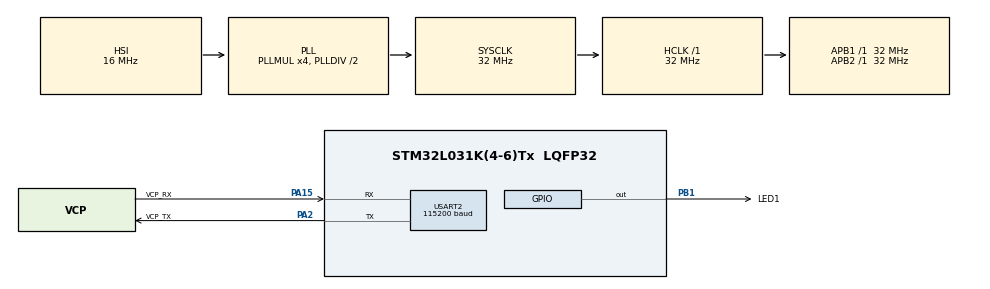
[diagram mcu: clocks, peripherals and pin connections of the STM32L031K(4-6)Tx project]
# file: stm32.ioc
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Mcu.Family=STM32L0
Mcu.Name=STM32L031K(4-6)Tx
Mcu.Package=LQFP32
NVIC.RTC_IRQn=true\:1\:0\:true\:true\:true\:2\:true
NVIC.USART2_IRQn=true\:2\:0\:true\:true\:true\:1\:true
PA13.GPIO_Label=TMS
PA13.Mode=Serial_Wire
PA13.Signal=SYS_SWDIO
PA14.GPIO_Label=TCK
PA14.Mode=Serial_Wire
PA14.Signal=SYS_SWCLK
PA15.GPIO_Label=VCP_RX
PA15.Mode=Asynchronous
PA15.Signal=USART2_RX
PA2.GPIO_Label=VCP_TX
PA2.Mode=Asynchronous
PA2.Signal=USART2_TX
PB1.GPIO_Label=LED1
PB1.GPIO_Speed=GPIO_SPEED_FREQ_HIGH
PB1.Signal=GPIO_Output
PC14-OSC32_IN.Signal=RCC_OSC32_IN
PC15-OSC32_OUT.Signal=RCC_OSC32_OUT
ProjectManager.HeapSize=0x200
ProjectManager.StackSize=0x400
ProjectManager.TargetToolchain=MDK-ARM V5
RCC.ADCFreq_Value=16000000
RCC.AHBFreq_Value=32000000
RCC.APB1Freq_Value=32000000
RCC.APB1TimFreq_Value=32000000
RCC.APB2Freq_Value=32000000
RCC.APB2TimFreq_Value=32000000
RCC.HCLKFreq_Value=32000000
RCC.HSE_VALUE=8000000
RCC.HSI16_VALUE=16000000
RCC.HSI48_VALUE=48000000
RCC.HSI_VALUE=16000000
RCC.LSE_VALUE=32768
RCC.MSI_VALUE=2097000
RCC.PLLMUL=RCC_PLLMUL_4
RCC.SYSCLKFreq_VALUE=32000000
RCC.SYSCLKSource=RCC_SYSCLKSOURCE_PLLCLK
RCC.VCOOutputFreq_Value=64000000
RTC.WakeUpClock-WakeUp=RTC_WAKEUPCLOCK_CK_SPRE_16BITS
RTC.WakeUpCounter-WakeUp=1
USART2.BaudRate=115200
USART2.VirtualMode-Asynchronous=VM_ASYNC
VP_RTC_VS_RTC_Activate.Mode=RTC_Enabled
VP_RTC_VS_RTC_Calendar.Mode=RTC_Calendar
VP_RTC_VS_RTC_WakeUp_intern.Mode=WakeUp
board=NUCLEO-L031K6

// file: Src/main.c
/* USER CODE BEGIN Header */
/**
  ******************************************************************************
  * @file           : main.c
  * @brief          : Main program body
  ******************************************************************************
  ** This notice applies to any and all portions of this file
  * that are not between comment pairs USER CODE BEGIN and
  * USER CODE END. Other portions of this file, whether
  * inserted by the user or by software development tools
  * are owned by their respective copyright owners.
  *
  * COPYRIGHT(c) 2018 STMicroelectronics
  *
  * Redistribution and use in source and binary forms, with or without modification,
  * are permitted provided that the following conditions are met:
  *   1. Redistributions of source code must retain the above copyright notice,
  *      this list of conditions and the following disclaimer.
  *   2. Redistributions in binary form must reproduce the above copyright notice,
  *      this list of conditions and the following disclaimer in the documentation
  *      and/or other materials provided with the distribution.
  *   3. Neither the name of STMicroelectronics nor the names of its contributors
  *      may be used to endorse or promote products derived from this software
  *      without specific prior written permission.
  *
  * THIS SOFTWARE IS PROVIDED BY THE COPYRIGHT HOLDERS AND CONTRIBUTORS "AS IS"
  * AND ANY EXPRESS OR IMPLIED WARRANTIES, INCLUDING, BUT NOT LIMITED TO, THE
  * IMPLIED WARRANTIES OF MERCHANTABILITY AND FITNESS FOR A PARTICULAR PURPOSE ARE
  * DISCLAIMED. IN NO EVENT SHALL THE COPYRIGHT HOLDER OR CONTRIBUTORS BE LIABLE
  * FOR ANY DIRECT, INDIRECT, INCIDENTAL, SPECIAL, EXEMPLARY, OR CONSEQUENTIAL
  * DAMAGES (INCLUDING, BUT NOT LIMITED TO, PROCUREMENT OF SUBSTITUTE GOODS OR
  * SERVICES; LOSS OF USE, DATA, OR PROFITS; OR BUSINESS INTERRUPTION) HOWEVER
  * CAUSED AND ON ANY THEORY OF LIABILITY, WHETHER IN CONTRACT, STRICT LIABILITY,
  * OR TORT (INCLUDING NEGLIGENCE OR OTHERWISE) ARISING IN ANY WAY OUT OF THE USE
  * OF THIS SOFTWARE, EVEN IF ADVISED OF THE POSSIBILITY OF SUCH DAMAGE.
  *
  ******************************************************************************
  */
/* USER CODE END Header */

#include "main.h"

RTC_HandleTypeDef hrtc;

UART_HandleTypeDef huart2;

void SystemClock_Config(void);
static void MX_GPIO_Init(void);
static void MX_USART2_UART_Init(void);
static void MX_RTC_Init(void);
static void MX_NVIC_Init(void);

int main(void)
{

  /* MCU Configuration--------------------------------------------------------*/

  /* Reset of all peripherals, Initializes the Flash interface and the Systick. */
  HAL_Init();

  /* Configure the system clock */
  SystemClock_Config();

  /* Initialize all configured peripherals */
  MX_GPIO_Init();
  MX_USART2_UART_Init();
  MX_RTC_Init();

  /* Initialize interrupts */
  MX_NVIC_Init();
  /* USER CODE BEGIN 2 */
  UNVSL_Usart_Init(&huart2, &unvsal_usart_ctrl);
	UNVSL_Delay_Init();
	HAL_GPIO_WritePin(LED1_GPIO_Port, LED1_Pin, GPIO_PIN_RESET);
	UNVSL_Delay_Ms(1000);
	HAL_GPIO_WritePin(LED1_GPIO_Port, LED1_Pin, GPIO_PIN_SET);
	UNVSL_Delay_Ms(1000);
  HAL_PWR_EnterSTANDBYMode();
  /* USER CODE END 2 */

  /* Infinite loop */
  while (1)
  {

    /* USER CODE BEGIN 3 */
		HAL_GPIO_WritePin(LED1_GPIO_Port, LED1_Pin, GPIO_PIN_RESET);
	  UNVSL_Delay_Us(100);
		HAL_GPIO_WritePin(LED1_GPIO_Port, LED1_Pin, GPIO_PIN_SET);
		UNVSL_Delay_Us(100);
//		printf("hello world!");
  }
  /* USER CODE END 3 */
}

void SystemClock_Config(void)
{
  RCC_OscInitTypeDef RCC_OscInitStruct = {0};
  RCC_ClkInitTypeDef RCC_ClkInitStruct = {0};
  RCC_PeriphCLKInitTypeDef PeriphClkInit = {0};

  /**Configure the main internal regulator output voltage
  */
  __HAL_PWR_VOLTAGESCALING_CONFIG(PWR_REGULATOR_VOLTAGE_SCALE1);
  /**Initializes the CPU, AHB and APB busses clocks
  */
  RCC_OscInitStruct.OscillatorType = RCC_OSCILLATORTYPE_HSI|RCC_OSCILLATORTYPE_LSI;
  RCC_OscInitStruct.HSIState = RCC_HSI_ON;
  RCC_OscInitStruct.HSICalibrationValue = RCC_HSICALIBRATION_DEFAULT;
  RCC_OscInitStruct.LSIState = RCC_LSI_ON;
  RCC_OscInitStruct.PLL.PLLState = RCC_PLL_ON;
  RCC_OscInitStruct.PLL.PLLSource = RCC_PLLSOURCE_HSI;
  RCC_OscInitStruct.PLL.PLLMUL = RCC_PLLMUL_4;
  RCC_OscInitStruct.PLL.PLLDIV = RCC_PLLDIV_2;
  if (HAL_RCC_OscConfig(&RCC_OscInitStruct) != HAL_OK)
  {
    Error_Handler();
  }
  /**Initializes the CPU, AHB and APB busses clocks
  */
  RCC_ClkInitStruct.ClockType = RCC_CLOCKTYPE_HCLK|RCC_CLOCKTYPE_SYSCLK
                              |RCC_CLOCKTYPE_PCLK1|RCC_CLOCKTYPE_PCLK2;
  RCC_ClkInitStruct.SYSCLKSource = RCC_SYSCLKSOURCE_PLLCLK;
  RCC_ClkInitStruct.AHBCLKDivider = RCC_SYSCLK_DIV1;
  RCC_ClkInitStruct.APB1CLKDivider = RCC_HCLK_DIV1;
  RCC_ClkInitStruct.APB2CLKDivider = RCC_HCLK_DIV1;

  if (HAL_RCC_ClockConfig(&RCC_ClkInitStruct, FLASH_LATENCY_1) != HAL_OK)
  {
    Error_Handler();
  }
  PeriphClkInit.PeriphClockSelection = RCC_PERIPHCLK_USART2|RCC_PERIPHCLK_RTC;
  PeriphClkInit.Usart2ClockSelection = RCC_USART2CLKSOURCE_PCLK1;
  PeriphClkInit.RTCClockSelection = RCC_RTCCLKSOURCE_LSI;
  if (HAL_RCCEx_PeriphCLKConfig(&PeriphClkInit) != HAL_OK)
  {
    Error_Handler();
  }
}

/**
  * @brief NVIC Configuration.
  * @retval None
  */
static void MX_NVIC_Init(void)
{
  /* USART2_IRQn interrupt configuration */
  HAL_NVIC_SetPriority(USART2_IRQn, 2, 0);
  HAL_NVIC_EnableIRQ(USART2_IRQn);
  /* RTC_IRQn interrupt configuration */
  HAL_NVIC_SetPriority(RTC_IRQn, 1, 0);
  HAL_NVIC_EnableIRQ(RTC_IRQn);
}

static void MX_RTC_Init(void)
{

  RTC_TimeTypeDef sTime = {0};
  RTC_DateTypeDef sDate = {0};

  /**Initialize RTC Only
  */
  hrtc.Instance = RTC;
  hrtc.Init.HourFormat = RTC_HOURFORMAT_24;
  hrtc.Init.AsynchPrediv = 127;
  hrtc.Init.SynchPrediv = 255;
  hrtc.Init.OutPut = RTC_OUTPUT_DISABLE;
  hrtc.Init.OutPutRemap = RTC_OUTPUT_REMAP_NONE;
  hrtc.Init.OutPutPolarity = RTC_OUTPUT_POLARITY_HIGH;
  hrtc.Init.OutPutType = RTC_OUTPUT_TYPE_OPENDRAIN;
  if (HAL_RTC_Init(&hrtc) != HAL_OK)
  {
    Error_Handler();
  }

  /**Initialize RTC and set the Time and Date
  */
  sTime.Hours = 0x0;
  sTime.Minutes = 0x0;
  sTime.Seconds = 0x0;
  sTime.DayLightSaving = RTC_DAYLIGHTSAVING_NONE;
  sTime.StoreOperation = RTC_STOREOPERATION_RESET;
  if (HAL_RTC_SetTime(&hrtc, &sTime, RTC_FORMAT_BCD) != HAL_OK)
  {
    Error_Handler();
  }
  sDate.WeekDay = RTC_WEEKDAY_MONDAY;
  sDate.Month = RTC_MONTH_JANUARY;
  sDate.Date = 0x1;
  sDate.Year = 0x0;

  if (HAL_RTC_SetDate(&hrtc, &sDate, RTC_FORMAT_BCD) != HAL_OK)
  {
    Error_Handler();
  }
  /**Enable the WakeUp
  */
  if (HAL_RTCEx_SetWakeUpTimer_IT(&hrtc, 1, RTC_WAKEUPCLOCK_CK_SPRE_16BITS) != HAL_OK)
  {
    Error_Handler();
  }

}

static void MX_USART2_UART_Init(void)
{

  huart2.Instance = USART2;
  huart2.Init.BaudRate = 115200;
  huart2.Init.WordLength = UART_WORDLENGTH_8B;
  huart2.Init.StopBits = UART_STOPBITS_1;
  huart2.Init.Parity = UART_PARITY_NONE;
  huart2.Init.Mode = UART_MODE_TX_RX;
  huart2.Init.HwFlowCtl = UART_HWCONTROL_NONE;
  huart2.Init.OverSampling = UART_OVERSAMPLING_16;
  huart2.Init.OneBitSampling = UART_ONE_BIT_SAMPLE_DISABLE;
  huart2.AdvancedInit.AdvFeatureInit = UART_ADVFEATURE_NO_INIT;
  if (HAL_UART_Init(&huart2) != HAL_OK)
  {
    Error_Handler();
  }

}

static void MX_GPIO_Init(void)
{
  GPIO_InitTypeDef GPIO_InitStruct = {0};

  /* GPIO Ports Clock Enable */
  __HAL_RCC_GPIOC_CLK_ENABLE();
  __HAL_RCC_GPIOA_CLK_ENABLE();
  __HAL_RCC_GPIOB_CLK_ENABLE();

  /*Configure GPIO pin Output Level */
  HAL_GPIO_WritePin(LED1_GPIO_Port, LED1_Pin, GPIO_PIN_RESET);

  /*Configure GPIO pin : LED1_Pin */
  GPIO_InitStruct.Pin = LED1_Pin;
  GPIO_InitStruct.Mode = GPIO_MODE_OUTPUT_PP;
  GPIO_InitStruct.Pull = GPIO_NOPULL;
  GPIO_InitStruct.Speed = GPIO_SPEED_FREQ_HIGH;
  HAL_GPIO_Init(LED1_GPIO_Port, &GPIO_InitStruct);

}

void Error_Handler(void)
{
}

/************************ (C) COPYRIGHT STMicroelectronics *****END OF FILE****/
